# MDR1986BE4 register map
Registers are 32-bit, access not given, no defined reset value unless marked. A register's access mark holds for its fields unless they carry their own. Addresses are absolute; registers are grouped by the start of their names; [hi:lo] are bit positions; {n}, {i} and the like mark numbered series.

## WWDG
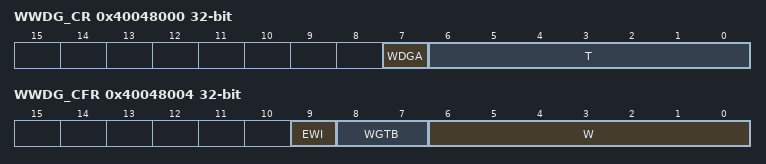
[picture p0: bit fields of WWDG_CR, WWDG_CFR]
0x40048000 WWDG_CR
  [7] WDGA, [6:0] T
0x40048004 WWDG_CFR
  [9] EWI, [8:7] WGTB, [6:0] W
0x40048008 WWDG_SR
  [0] EWIF

## IWDG
0x40050000 IWDG_KR
  [15:0] KEY
0x40050004 IWDG_PR
  [2:0] PR
0x40050008 IWDG_RLR
  [11:0] RLR
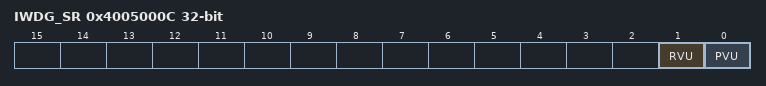
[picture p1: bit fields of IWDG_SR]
0x4005000C IWDG_SR
  [1] RVU, [0] PVU

## BKP
{0x40060000+4i} BKP_REG_{i:02} (i=0..9)
  [31:0] BKP_REG
0x40060028 BKP_REG_0A
  [31:0] BKP_REG
0x4006002C BKP_REG_0B
  [31:0] BKP_REG
0x40060030 BKP_REG_0C
  [31:0] BKP_REG
0x40060034 BKP_REG_0D
  [31:0] BKP_REG
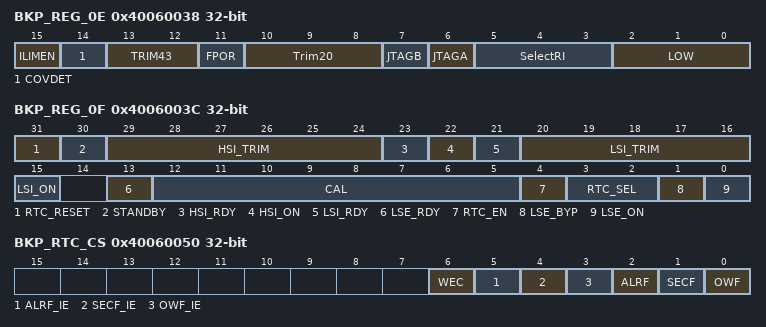
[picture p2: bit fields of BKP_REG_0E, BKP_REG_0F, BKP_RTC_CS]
0x40060038 BKP_REG_0E
  [15] ILIMEN, [14] COVDET, [13:12] TRIM43, [11] FPOR, [10:8] Trim20, [7] JTAGB, [6] JTAGA, [5:3] SelectRI, [2:0] LOW
0x4006003C BKP_REG_0F
  [31] RTC_RESET, [30] STANDBY, [29:24] HSI_TRIM, [23] HSI_RDY, [22] HSI_ON, [21] LSI_RDY, [20:16] LSI_TRIM, [15] LSI_ON, [13] LSE_RDY, [12:5] CAL, [4] RTC_EN, [3:2] RTC_SEL, [1] LSE_BYP, [0] LSE_ON
0x40060040 BKP_RTC_CNT
  [31:0] RTC_CNT
0x40060044 BKP_RTC_DIV
  [19:0] RTC_DIV
0x40060048 BKP_RTC_PRL
  [19:0] RTC_PRL
0x4006004C BKP_RTC_ALRM
  [31:0] RTC_ALRM
0x40060050 BKP_RTC_CS
  [6] WEC, [5] ALRF_IE, [4] SECF_IE, [3] OWF_IE, [2] ALRF, [1] SECF, [0] OWF

## ADCIU
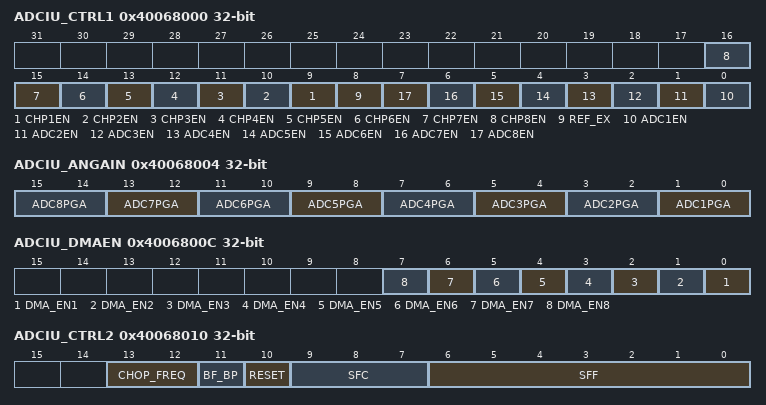
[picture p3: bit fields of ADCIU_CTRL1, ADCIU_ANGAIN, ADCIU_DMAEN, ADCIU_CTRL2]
0x40068000 ADCIU_CTRL1
  [n+8] CHP{n}EN (n=1..8), [8] REF_EX, [n-1] ADC{n}EN (n=1..8)
0x40068004 ADCIU_ANGAIN
  [2n-1:2n-2] ADC{n}PGA (n=1..8)
0x40068008 ADCIU_DIGGAN
  [5:0] ADCPGA
0x4006800C ADCIU_DMAEN
  [n-1] DMA_EN{n} (n=1..8)
0x40068010 ADCIU_CTRL2
  [13:12] CHOP_FREQ, [11] BF_BP, [10] RESET, [9:7] SFC, [6:0] SFF
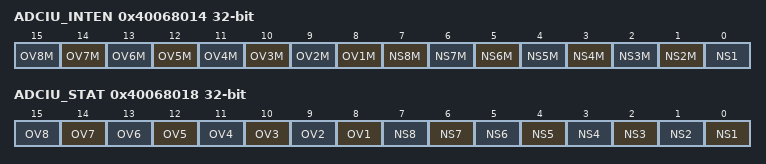
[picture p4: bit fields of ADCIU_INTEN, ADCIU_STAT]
0x40068014 ADCIU_INTEN
  [n+7] OV{n}M (n=1..8), [n-1] NS{n}M (n=2..8), [0] NS1
0x40068018 ADCIU_STAT
  [n+7] OV{n} (n=1..8), [n-1] NS{n} (n=1..8)
{0x4006801C+4i} ADCIU_F{i}_DAT (i=0..7)
  [23:0] SMPLE

## CRC
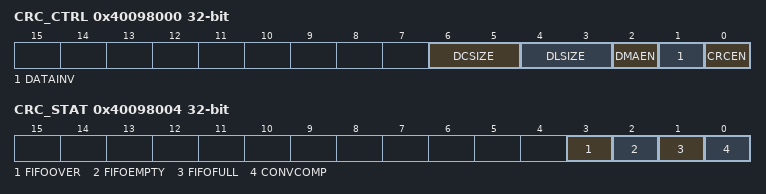
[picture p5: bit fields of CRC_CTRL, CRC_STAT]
0x40098000 CRC_CTRL
  [6:5] DCSIZE, [4:3] DLSIZE, [2] DMAEN, [1] DATAINV, [0] CRCEN
0x40098004 CRC_STAT
  [3] FIFOOVER, [2] FIFOEMPTY, [1] FIFOFULL, [0] CONVCOMP
0x40098008 CRC_DATAI
  [31:0] DATA_IN
0x4009800C CRC_VAL
  [15:0] CRCOUT
0x40098010 CRC_POL
  [16:0] CRC_POL

## UART1
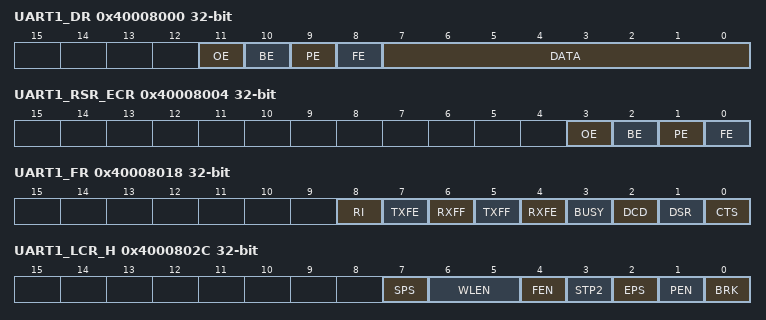
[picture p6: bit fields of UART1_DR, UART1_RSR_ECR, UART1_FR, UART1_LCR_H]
0x40008000 UART1_DR
  [11] OE, [10] BE, [9] PE, [8] FE, [7:0] DATA
0x40008004 UART1_RSR_ECR
  [3] OE, [2] BE, [1] PE, [0] FE
0x40008018 UART1_FR
  [8] RI, [7] TXFE, [6] RXFF, [5] TXFF, [4] RXFE, [3] BUSY, [2] DCD, [1] DSR, [0] CTS
0x40008020 UART1_ILPR
  [7:0] ILPDVSR
0x40008024 UART1_IBRD
  [15:0] BAUD_DIVINT
0x40008028 UART1_FBRD
  [5:0] BAUD_DIVFRAC
0x4000802C UART1_LCR_H
  [7] SPS, [6:5] WLEN, [4] FEN, [3] STP2, [2] EPS, [1] PEN, [0] BRK
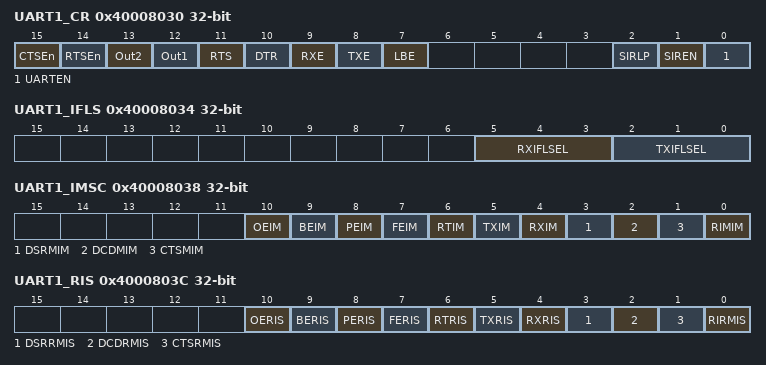
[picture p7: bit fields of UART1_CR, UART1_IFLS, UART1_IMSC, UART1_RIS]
0x40008030 UART1_CR
  [15] CTSEn, [14] RTSEn, [13] Out2, [12] Out1, [11] RTS, [10] DTR, [9] RXE, [8] TXE, [7] LBE, [2] SIRLP, [1] SIREN, [0] UARTEN
0x40008034 UART1_IFLS
  [5:3] RXIFLSEL, [2:0] TXIFLSEL
0x40008038 UART1_IMSC
  [10] OEIM, [9] BEIM, [8] PEIM, [7] FEIM, [6] RTIM, [5] TXIM, [4] RXIM, [3] DSRMIM, [2] DCDMIM, [1] CTSMIM, [0] RIMIM
0x4000803C UART1_RIS
  [10] OERIS, [9] BERIS, [8] PERIS, [7] FERIS, [6] RTRIS, [5] TXRIS, [4] RXRIS, [3] DSRRMIS, [2] DCDRMIS, [1] CTSRMIS, [0] RIRMIS
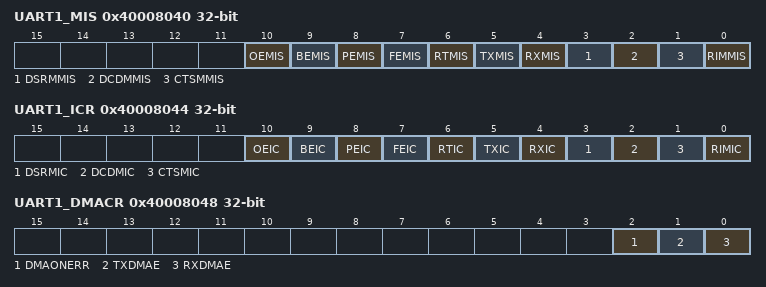
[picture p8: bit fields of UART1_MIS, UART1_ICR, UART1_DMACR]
0x40008040 UART1_MIS
  [10] OEMIS, [9] BEMIS, [8] PEMIS, [7] FEMIS, [6] RTMIS, [5] TXMIS, [4] RXMIS, [3] DSRMMIS, [2] DCDMMIS, [1] CTSMMIS, [0] RIMMIS
0x40008044 UART1_ICR
  [10] OEIC, [9] BEIC, [8] PEIC, [7] FEIC, [6] RTIC, [5] TXIC, [4] RXIC, [3] DSRMIC, [2] DCDMIC, [1] CTSMIC, [0] RIMIC
0x40008048 UART1_DMACR
  [2] DMAONERR, [1] TXDMAE, [0] RXDMAE

## UART2
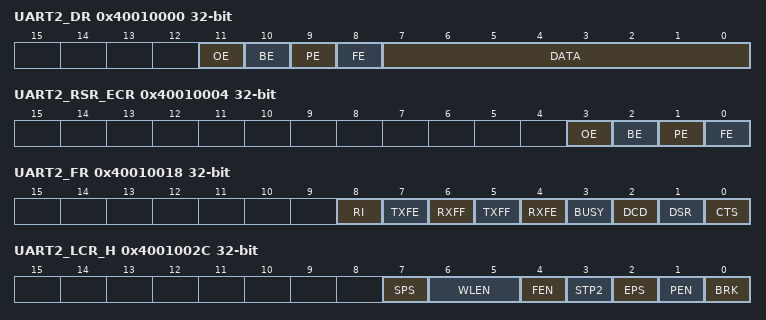
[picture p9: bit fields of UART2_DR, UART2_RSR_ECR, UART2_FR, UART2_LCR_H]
0x40010000 UART2_DR
  [11] OE, [10] BE, [9] PE, [8] FE, [7:0] DATA
0x40010004 UART2_RSR_ECR
  [3] OE, [2] BE, [1] PE, [0] FE
0x40010018 UART2_FR
  [8] RI, [7] TXFE, [6] RXFF, [5] TXFF, [4] RXFE, [3] BUSY, [2] DCD, [1] DSR, [0] CTS
0x40010020 UART2_ILPR
  [7:0] ILPDVSR
0x40010024 UART2_IBRD
  [15:0] BAUD_DIVINT
0x40010028 UART2_FBRD
  [5:0] BAUD_DIVFRAC
0x4001002C UART2_LCR_H
  [7] SPS, [6:5] WLEN, [4] FEN, [3] STP2, [2] EPS, [1] PEN, [0] BRK
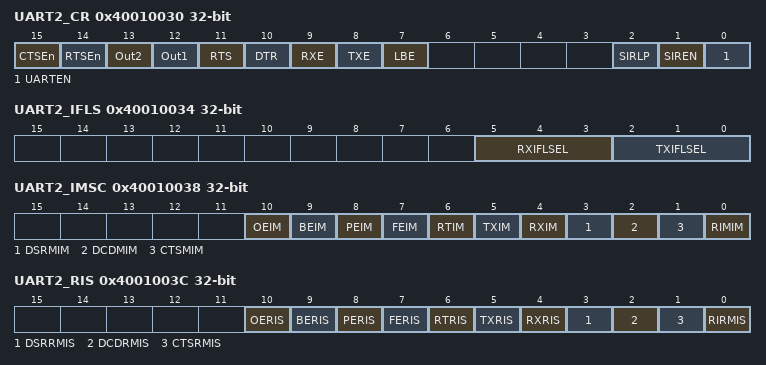
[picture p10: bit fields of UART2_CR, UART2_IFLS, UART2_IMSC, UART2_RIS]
0x40010030 UART2_CR
  [15] CTSEn, [14] RTSEn, [13] Out2, [12] Out1, [11] RTS, [10] DTR, [9] RXE, [8] TXE, [7] LBE, [2] SIRLP, [1] SIREN, [0] UARTEN
0x40010034 UART2_IFLS
  [5:3] RXIFLSEL, [2:0] TXIFLSEL
0x40010038 UART2_IMSC
  [10] OEIM, [9] BEIM, [8] PEIM, [7] FEIM, [6] RTIM, [5] TXIM, [4] RXIM, [3] DSRMIM, [2] DCDMIM, [1] CTSMIM, [0] RIMIM
0x4001003C UART2_RIS
  [10] OERIS, [9] BERIS, [8] PERIS, [7] FERIS, [6] RTRIS, [5] TXRIS, [4] RXRIS, [3] DSRRMIS, [2] DCDRMIS, [1] CTSRMIS, [0] RIRMIS
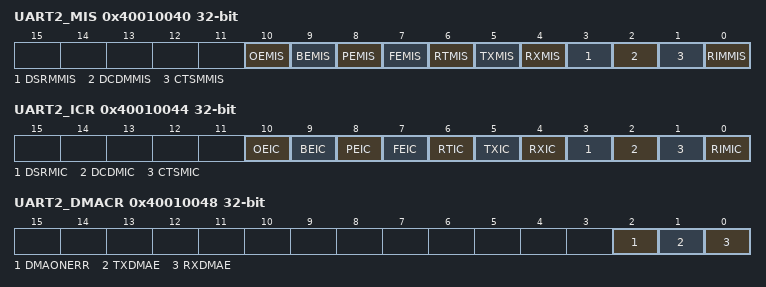
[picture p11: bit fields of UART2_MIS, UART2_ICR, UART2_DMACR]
0x40010040 UART2_MIS
  [10] OEMIS, [9] BEMIS, [8] PEMIS, [7] FEMIS, [6] RTMIS, [5] TXMIS, [4] RXMIS, [3] DSRMMIS, [2] DCDMMIS, [1] CTSMMIS, [0] RIMMIS
0x40010044 UART2_ICR
  [10] OEIC, [9] BEIC, [8] PEIC, [7] FEIC, [6] RTIC, [5] TXIC, [4] RXIC, [3] DSRMIC, [2] DCDMIC, [1] CTSMIC, [0] RIMIC
0x40010048 UART2_DMACR
  [2] DMAONERR, [1] TXDMAE, [0] RXDMAE
